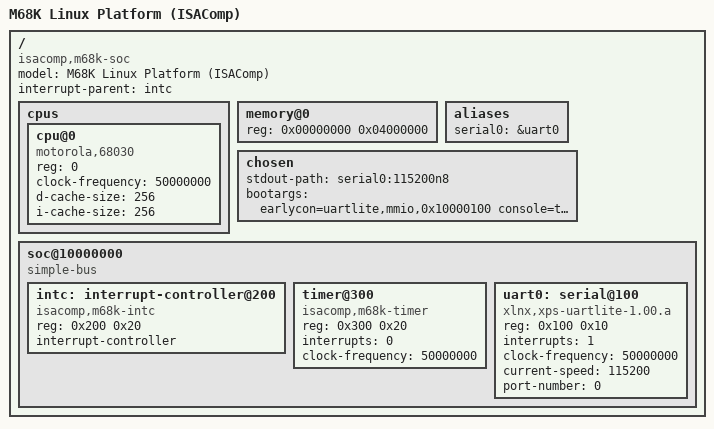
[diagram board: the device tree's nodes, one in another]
// SPDX-License-Identifier: GPL-2.0
// Device tree for M68K processor generated by ISAComp
// Target: MC68030 with MMU for Linux boot
/dts-v1/;

/ {
	compatible = "isacomp,m68k-soc";
	model = "M68K Linux Platform (ISAComp)";

	#address-cells = <1>;
	#size-cells = <1>;

	interrupt-parent = <&intc>;

	cpus {
		#address-cells = <1>;
		#size-cells = <0>;

		cpu@0 {
			device_type = "cpu";
			compatible = "motorola,68030";
			reg = <0>;
			clock-frequency = <50000000>;  // 50 MHz
			// MC68030 has built-in MMU
			d-cache-size = <256>;
			i-cache-size = <256>;
		};
	};

	// 64MB memory starting at 0x00000000
	// Exception vectors occupy first 1KB (0x000-0x3FF)
	// Kernel loads at 0x00001000
	memory@0 {
		device_type = "memory";
		reg = <0x00000000 0x04000000>;  // 64MB
	};

	aliases {
		serial0 = &uart0;
	};

	chosen {
		stdout-path = "serial0:115200n8";
		bootargs = "earlycon=uartlite,mmio,0x10000100 console=ttyUL0,115200";
	};

	// Peripheral region at 0x10000000 (16MB I/O space)
	soc@10000000 {
		compatible = "simple-bus";
		ranges = <0 0x10000000 0x1000000>;

		#address-cells = <1>;
		#size-cells = <1>;

		// M68K Interrupt Controller
		// Maps external interrupts to M68K exception vectors
		// Autovector interrupts use vectors 25-31 (IPL1-7)
		// User vectors available 64-255
		intc: interrupt-controller@200 {
			compatible = "isacomp,m68k-intc";
			reg = <0x200 0x20>;
			interrupt-controller;
			#interrupt-cells = <1>;
		};

		// Timer (similar to ColdFire PIT)
		// Generates periodic interrupts for Linux scheduler
		timer@300 {
			compatible = "isacomp,m68k-timer";
			reg = <0x300 0x20>;
			interrupts = <0>;  // Source 0 -> INTC vector IVR+0 (default: 64)
			clock-frequency = <50000000>;
		};

		// Xilinx UARTLite serial port
		// Same as J2 platform for compatibility
		uart0: serial@100 {
			compatible = "xlnx,xps-uartlite-1.00.a";
			reg = <0x100 0x10>;
			interrupts = <1>;  // Source 1 -> INTC vector IVR+1 (default: 65)
			clock-frequency = <50000000>;
			current-speed = <115200>;
			device_type = "serial";
			port-number = <0>;
		};
	};
};
